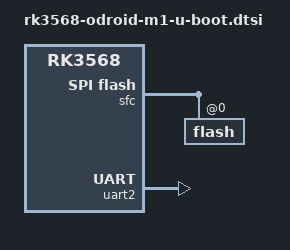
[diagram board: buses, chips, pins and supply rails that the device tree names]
// SPDX-License-Identifier: GPL-2.0+

#include "rk356x-u-boot.dtsi"

/ {
	chosen {
		stdout-path = &uart2;
	};
};

&fspi_dual_io_pins {
	bootph-all;
};

&sdhci {
	cap-mmc-highspeed;
	mmc-ddr-1_8v;
	mmc-hs200-1_8v;
	mmc-hs400-1_8v;
	mmc-hs400-enhanced-strobe;
	pinctrl-0 = <&emmc_bus8 &emmc_clk &emmc_cmd &emmc_datastrobe>;
};

&sfc {
	bootph-pre-ram;
	u-boot,spl-sfc-no-dma;

	flash@0 {
		bootph-pre-ram;
	};
};

&uart2 {
	bootph-all;
	clock-frequency = <24000000>;
	status = "okay";
};
